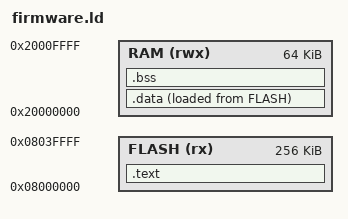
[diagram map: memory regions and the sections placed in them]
MEMORY
{
    FLASH (rx)  : ORIGIN = 0x08000000, LENGTH = 256K
    RAM   (rwx) : ORIGIN = 0x20000000, LENGTH = 64K
}

ENTRY(Reset_Handler)

SECTIONS
{
    .text :
    {
        . = ALIGN(4);
        KEEP(*(.isr_vector))
        *(.text .text.*)
        *(.rodata .rodata.*)
        . = ALIGN(4);
        __text_end__ = .;
    } > FLASH

    .data :
    {
        . = ALIGN(4);
        __data_start__ = .;
        *(.data .data.*)
        . = ALIGN(4);
        __data_end__ = .;
    } > RAM AT> FLASH

    __data_load_start__ = LOADADDR(.data);

    .bss (NOLOAD) :
    {
        . = ALIGN(4);
        __bss_start__ = .;
        *(.bss .bss.* COMMON)
        . = ALIGN(4);
        __bss_end__ = .;
    } > RAM

    ASSERT(__bss_end__ <= ORIGIN(RAM) + LENGTH(RAM), "RAM overflow")
}
